# SiFive_FE200 register map
File version: 0.1
From SiFive,FE200,model device generator
Registers are 8-bit, read-write, no defined reset value unless marked. A register's access mark holds for its fields unless they carry their own. Offsets are from the block's base; lines under a group give offsets from that group; [hi:lo] are bit positions; {n}, {i} and the like mark numbered series; 'fields as' and 'values as' point back to an identical list; <NAME> marks a mode.

## Memory map
0x00004000 sifive_test0_0 size 0x1000 — From sifive,test0,control peripheral generator
0x02000000 sifive_clic0_0 size 0x1000000 — From sifive,clic0,control peripheral generator

## sifive_clic0_0 — From sifive,clic0,control peripheral generator
Base 0x02000000
0x00 msip_0 32-bit — MSIP Register for hart 0
0x4000 mtimecmp_0 64-bit — MTIMECMP Register for hart 0
0xBFF8 mtime 64-bit
{0x800000+i} clicintip_{i} (i=0..142) — CLICINTIP Register for interrupt id {i}
{0x800400+i} clicintie_{i} (i=0..142) — CLICINTIE Register for interrupt id {i}
{0x800800+i} clicintctl_{i} (i=0..142) — CLICINTCTL Register for interrupt id {i}
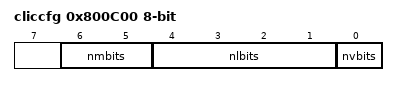
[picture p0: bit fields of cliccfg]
0x800C00 cliccfg
  [6:5] nmbits ro — Determines the number of Mode bits available in clicintctl.
  [4:1] nlbits — Determines the number of Level bits available in clicintctl.
  [0] nvbits — When set, selective hardware vectoring is enabled.

## sifive_test0_0 — From sifive,test0,control peripheral generator
Base 0x00004000
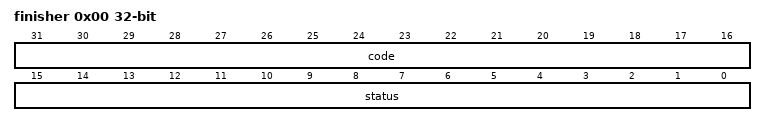
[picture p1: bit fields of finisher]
0x00 finisher 32-bit — Test finisher register
  [31:16] code — Finisher code
  [15:0] status — Test status
